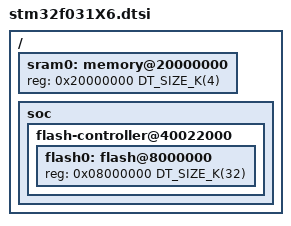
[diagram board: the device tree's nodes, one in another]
/*
 * Copyright (c) 2021 Sebastian Schwabe <sebastian.schwabe@mailbox.tu-dresden.de>
 *
 * SPDX-License-Identifier: Apache-2.0
 */

#include <mem.h>
#include <st/f0/stm32f031.dtsi>

/ {
	sram0: memory@20000000 {
		reg = <0x20000000 DT_SIZE_K(4)>;
	};

	soc {
		flash-controller@40022000 {
			flash0: flash@8000000 {
				reg = <0x08000000 DT_SIZE_K(32)>;
			};
		};
	};
};
